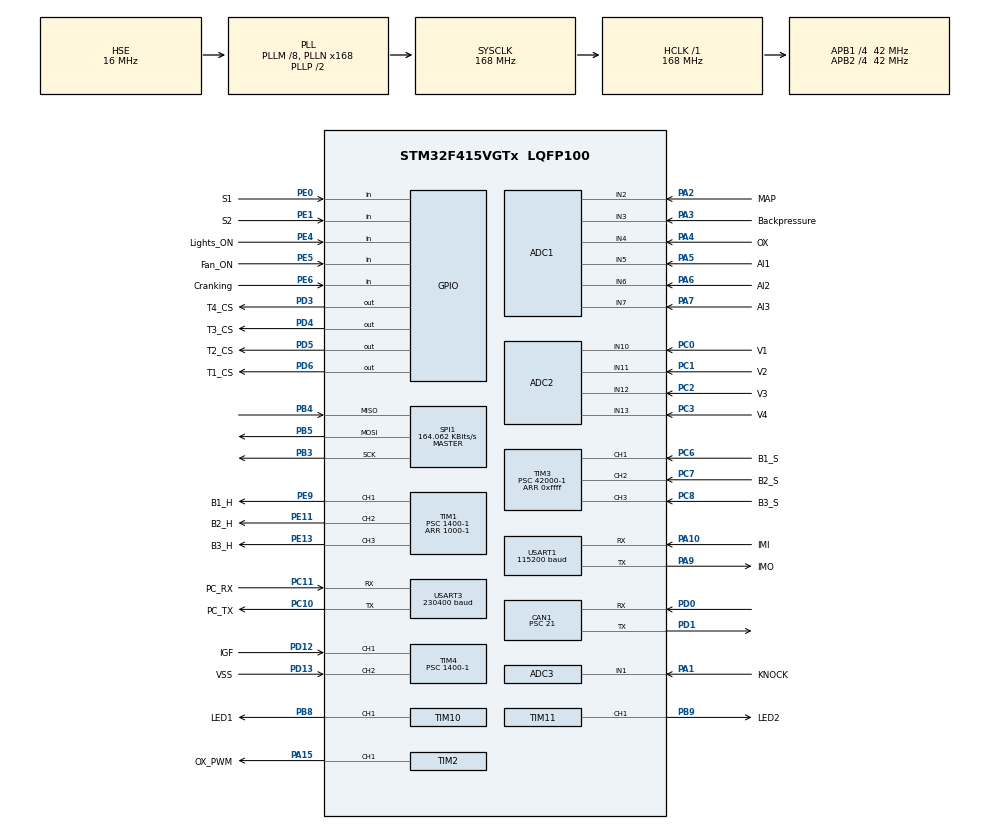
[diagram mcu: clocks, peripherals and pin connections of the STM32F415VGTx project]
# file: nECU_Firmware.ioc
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ADC1.Channel-18\#ChannelRegularConversion=ADC_CHANNEL_3
ADC1.Channel-19\#ChannelRegularConversion=ADC_CHANNEL_4
ADC1.Channel-20\#ChannelRegularConversion=ADC_CHANNEL_5
ADC1.Channel-21\#ChannelRegularConversion=ADC_CHANNEL_6
ADC1.Channel-22\#ChannelRegularConversion=ADC_CHANNEL_7
ADC1.Channel-23\#ChannelRegularConversion=ADC_CHANNEL_TEMPSENSOR
ADC1.Channel-24\#ChannelRegularConversion=ADC_CHANNEL_VREFINT
ADC1.Channel-3\#ChannelRegularConversion=ADC_CHANNEL_2
ADC1.ClockPrescaler=ADC_CLOCK_SYNC_PCLK_DIV8
ADC1.ContinuousConvMode=ENABLE
ADC1.DMAContinuousRequests=ENABLE
ADC1.DiscontinuousConvMode=DISABLE
ADC1.EOCSelection=ADC_EOC_SEQ_CONV
ADC1.ExternalTrigConv=ADC_SOFTWARE_START
ADC1.InjNumberOfConversion=0
ADC1.NbrOfConversion=8
ADC1.NbrOfConversionFlag=1
ADC1.Rank-18\#ChannelRegularConversion=2
ADC1.Rank-19\#ChannelRegularConversion=3
ADC1.Rank-20\#ChannelRegularConversion=4
ADC1.Rank-21\#ChannelRegularConversion=5
ADC1.Rank-22\#ChannelRegularConversion=6
ADC1.Rank-23\#ChannelRegularConversion=7
ADC1.Rank-24\#ChannelRegularConversion=8
ADC1.SamplingTime-18\#ChannelRegularConversion=ADC_SAMPLETIME_480CYCLES
ADC1.SamplingTime-19\#ChannelRegularConversion=ADC_SAMPLETIME_480CYCLES
ADC1.SamplingTime-20\#ChannelRegularConversion=ADC_SAMPLETIME_480CYCLES
ADC1.SamplingTime-21\#ChannelRegularConversion=ADC_SAMPLETIME_480CYCLES
ADC1.SamplingTime-22\#ChannelRegularConversion=ADC_SAMPLETIME_480CYCLES
ADC1.SamplingTime-23\#ChannelRegularConversion=ADC_SAMPLETIME_480CYCLES
ADC1.SamplingTime-24\#ChannelRegularConversion=ADC_SAMPLETIME_480CYCLES
ADC1.SamplingTime-3\#ChannelRegularConversion=ADC_SAMPLETIME_480CYCLES
ADC1.ScanConvMode=ENABLE
ADC1.master=1
ADC2.Channel-1\#ChannelRegularConversion=ADC_CHANNEL_10
ADC2.Channel-2\#ChannelRegularConversion=ADC_CHANNEL_11
ADC2.Channel-3\#ChannelRegularConversion=ADC_CHANNEL_12
ADC2.Channel-4\#ChannelRegularConversion=ADC_CHANNEL_13
ADC2.ClockPrescaler=ADC_CLOCK_SYNC_PCLK_DIV8
ADC2.ContinuousConvMode=ENABLE
ADC2.DMAContinuousRequests=ENABLE
ADC2.EOCSelection=ADC_EOC_SEQ_CONV
ADC2.ExternalTrigConv=ADC_SOFTWARE_START
ADC2.NbrOfConversion=4
ADC2.NbrOfConversionFlag=1
ADC2.Rank-1\#ChannelRegularConversion=1
ADC2.Rank-2\#ChannelRegularConversion=2
ADC2.Rank-3\#ChannelRegularConversion=3
ADC2.Rank-4\#ChannelRegularConversion=4
ADC2.SamplingTime-1\#ChannelRegularConversion=ADC_SAMPLETIME_480CYCLES
ADC2.SamplingTime-2\#ChannelRegularConversion=ADC_SAMPLETIME_480CYCLES
ADC2.SamplingTime-3\#ChannelRegularConversion=ADC_SAMPLETIME_480CYCLES
ADC2.SamplingTime-4\#ChannelRegularConversion=ADC_SAMPLETIME_480CYCLES
ADC2.ScanConvMode=ENABLE
ADC3.Channel-1\#ChannelRegularConversion=ADC_CHANNEL_1
ADC3.ClockPrescaler=ADC_CLOCK_SYNC_PCLK_DIV8
ADC3.ContinuousConvMode=DISABLE
ADC3.DMAContinuousRequests=ENABLE
ADC3.EOCSelection=ADC_EOC_SEQ_CONV
ADC3.ExternalTrigConv=ADC_EXTERNALTRIGCONV_T8_TRGO
ADC3.NbrOfConversion=1
ADC3.NbrOfConversionFlag=1
ADC3.Rank-1\#ChannelRegularConversion=1
ADC3.SamplingTime-1\#ChannelRegularConversion=ADC_SAMPLETIME_84CYCLES
ADC3.ScanConvMode=ENABLE
CAN1.ABOM=ENABLE
CAN1.AWUM=ENABLE
CAN1.BS1=CAN_BS1_2TQ
CAN1.BS2=CAN_BS2_1TQ
CAN1.CalculateBaudRate=500000
CAN1.CalculateTimeBit=2000
CAN1.CalculateTimeQuantum=500.0
CAN1.Prescaler=21
CAN1.SJW=CAN_SJW_2TQ
CAN1.TTCM=DISABLE
Dma.ADC1.3.Direction=DMA_PERIPH_TO_MEMORY
Dma.ADC1.3.FIFOMode=DMA_FIFOMODE_DISABLE
Dma.ADC1.3.Instance=DMA2_Stream0
Dma.ADC1.3.MemDataAlignment=DMA_MDATAALIGN_HALFWORD
Dma.ADC1.3.MemInc=DMA_MINC_ENABLE
Dma.ADC1.3.Mode=DMA_CIRCULAR
Dma.ADC1.3.PeriphDataAlignment=DMA_PDATAALIGN_HALFWORD
Dma.ADC1.3.PeriphInc=DMA_PINC_DISABLE
Dma.ADC1.3.Priority=DMA_PRIORITY_LOW
Dma.ADC2.0.Direction=DMA_PERIPH_TO_MEMORY
Dma.ADC2.0.FIFOMode=DMA_FIFOMODE_DISABLE
Dma.ADC2.0.Instance=DMA2_Stream3
Dma.ADC2.0.MemDataAlignment=DMA_MDATAALIGN_HALFWORD
Dma.ADC2.0.MemInc=DMA_MINC_ENABLE
Dma.ADC2.0.Mode=DMA_CIRCULAR
Dma.ADC2.0.PeriphDataAlignment=DMA_PDATAALIGN_HALFWORD
Dma.ADC2.0.PeriphInc=DMA_PINC_DISABLE
Dma.ADC2.0.Priority=DMA_PRIORITY_LOW
Dma.ADC3.1.Direction=DMA_PERIPH_TO_MEMORY
Dma.ADC3.1.FIFOMode=DMA_FIFOMODE_DISABLE
Dma.ADC3.1.Instance=DMA2_Stream1
Dma.ADC3.1.MemDataAlignment=DMA_MDATAALIGN_HALFWORD
Dma.ADC3.1.MemInc=DMA_MINC_ENABLE
Dma.ADC3.1.Mode=DMA_CIRCULAR
Dma.ADC3.1.PeriphDataAlignment=DMA_PDATAALIGN_HALFWORD
Dma.ADC3.1.PeriphInc=DMA_PINC_DISABLE
Dma.ADC3.1.Priority=DMA_PRIORITY_HIGH
Dma.Request0=ADC2
Dma.Request1=ADC3
Dma.Request2=USART1_TX
Dma.Request3=ADC1
Dma.USART1_TX.2.Direction=DMA_MEMORY_TO_PERIPH
Dma.USART1_TX.2.FIFOMode=DMA_FIFOMODE_DISABLE
Dma.USART1_TX.2.Instance=DMA2_Stream7
Dma.USART1_TX.2.MemDataAlignment=DMA_MDATAALIGN_BYTE
Dma.USART1_TX.2.MemInc=DMA_MINC_ENABLE
Dma.USART1_TX.2.Mode=DMA_NORMAL
Dma.USART1_TX.2.PeriphDataAlignment=DMA_PDATAALIGN_BYTE
Dma.USART1_TX.2.PeriphInc=DMA_PINC_DISABLE
Dma.USART1_TX.2.Priority=DMA_PRIORITY_HIGH
Mcu.Family=STM32F4
Mcu.Name=STM32F415VGTx
Mcu.Package=LQFP100
NVIC.CAN1_RX0_IRQn=true\:0\:3\:false\:false\:true\:true\:true\:true
NVIC.DMA2_Stream0_IRQn=true\:0\:0\:false\:false\:true\:true\:true\:true
NVIC.DMA2_Stream1_IRQn=true\:0\:2\:true\:false\:true\:false\:true\:true
NVIC.DMA2_Stream3_IRQn=true\:0\:3\:true\:false\:true\:false\:true\:true
NVIC.PriorityGroup=NVIC_PRIORITYGROUP_2
NVIC.SPI1_IRQn=true\:0\:2\:true\:false\:true\:true\:true\:true
NVIC.TIM3_IRQn=true\:1\:2\:true\:false\:true\:true\:true\:true
NVIC.TIM4_IRQn=true\:1\:3\:true\:false\:true\:true\:true\:true
NVIC.USART3_IRQn=true\:1\:1\:true\:false\:true\:true\:true\:true
PA1.GPIO_Label=KNOCK
PA1.Signal=ADCx_IN1
PA10.GPIO_Label=IMI
PA10.Mode=Asynchronous
PA10.Signal=USART1_RX
PA13.Mode=Serial_Wire
PA13.Signal=SYS_JTMS-SWDIO
PA14.Mode=Serial_Wire
PA14.Signal=SYS_JTCK-SWCLK
PA15.GPIO_Label=OX_PWM
PA15.Signal=S_TIM2_CH1_ETR
PA2.GPIO_Label=MAP
PA2.Signal=ADCx_IN2
PA3.GPIO_Label=Backpressure
PA3.Signal=ADCx_IN3
PA4.GPIO_Label=OX
PA4.Signal=ADCx_IN4
PA5.GPIO_Label=AI1
PA5.Signal=ADCx_IN5
PA6.GPIO_Label=AI2
PA6.Signal=ADCx_IN6
PA7.GPIO_Label=AI3
PA7.Signal=ADCx_IN7
PA9.GPIO_Label=IMO
PA9.Mode=Asynchronous
PA9.Signal=USART1_TX
PB3.Mode=Full_Duplex_Master
PB3.Signal=SPI1_SCK
PB4.Mode=Full_Duplex_Master
PB4.Signal=SPI1_MISO
PB5.Mode=Full_Duplex_Master
PB5.Signal=SPI1_MOSI
PB8.GPIO_Label=LED1
PB8.Signal=S_TIM10_CH1
PB9.GPIO_Label=LED2
PB9.Signal=S_TIM11_CH1
PC0.GPIO_Label=V1
PC0.Signal=ADCx_IN10
PC1.GPIO_Label=V2
PC1.Signal=ADCx_IN11
PC10.GPIO_Label=PC_TX
PC10.Mode=Asynchronous
PC10.Signal=USART3_TX
PC11.GPIO_Label=PC_RX
PC11.Mode=Asynchronous
PC11.Signal=USART3_RX
PC14-OSC32_IN.Mode=LSE-External-Oscillator
PC14-OSC32_IN.Signal=RCC_OSC32_IN
PC15-OSC32_OUT.Mode=LSE-External-Oscillator
PC15-OSC32_OUT.Signal=RCC_OSC32_OUT
PC2.GPIO_Label=V3
PC2.Signal=ADCx_IN12
PC3.GPIO_Label=V4
PC3.Signal=ADCx_IN13
PC6.GPIO_Label=B1_S
PC6.GPIO_PuPd=GPIO_PULLDOWN
PC6.Signal=S_TIM3_CH1
PC7.GPIO_Label=B2_S
PC7.GPIO_PuPd=GPIO_PULLDOWN
PC7.Signal=S_TIM3_CH2
PC8.GPIO_Label=B3_S
PC8.GPIO_PuPd=GPIO_PULLDOWN
PC8.Signal=S_TIM3_CH3
PD0.Mode=CAN_Activate
PD0.Signal=CAN1_RX
PD1.Mode=CAN_Activate
PD1.Signal=CAN1_TX
PD12.GPIO_Label=IGF
PD12.GPIO_PuPd=GPIO_PULLDOWN
PD12.Signal=S_TIM4_CH1
PD13.GPIO_Label=VSS
PD13.GPIO_PuPd=GPIO_PULLDOWN
PD13.Signal=S_TIM4_CH2
PD3.GPIO_Label=T4_CS
PD3.PinState=GPIO_PIN_SET
PD3.Signal=GPIO_Output
PD4.GPIO_Label=T3_CS
PD4.PinState=GPIO_PIN_SET
PD4.Signal=GPIO_Output
PD5.GPIO_Label=T2_CS
PD5.PinState=GPIO_PIN_SET
PD5.Signal=GPIO_Output
PD6.GPIO_Label=T1_CS
PD6.PinState=GPIO_PIN_SET
PD6.Signal=GPIO_Output
PE0.GPIO_Label=S1
PE0.Signal=GPIO_Input
PE1.GPIO_Label=S2
PE1.Signal=GPIO_Input
PE11.GPIO_Label=B2_H
PE11.Signal=S_TIM1_CH2
PE13.GPIO_Label=B3_H
PE13.Signal=S_TIM1_CH3
PE4.GPIO_Label=Lights_ON
PE4.Signal=GPIO_Input
PE5.GPIO_Label=Fan_ON
PE5.Signal=GPIO_Input
PE6.GPIO_Label=Cranking
PE6.GPIO_PuPd=GPIO_NOPULL
PE6.Signal=GPIO_Input
PE9.GPIO_Label=B1_H
PE9.Signal=S_TIM1_CH1
PH0-OSC_IN.Mode=HSE-External-Oscillator
PH0-OSC_IN.Signal=RCC_OSC_IN
PH1-OSC_OUT.Mode=HSE-External-Oscillator
PH1-OSC_OUT.Signal=RCC_OSC_OUT
ProjectManager.HeapSize=0x800
ProjectManager.StackSize=0x1000
ProjectManager.TargetToolchain=STM32CubeIDE
RCC.48MHZClocksFreq_Value=84000000
RCC.AHBFreq_Value=168000000
RCC.APB1CLKDivider=RCC_HCLK_DIV4
RCC.APB1Freq_Value=42000000
RCC.APB1TimFreq_Value=84000000
RCC.APB2CLKDivider=RCC_HCLK_DIV4
RCC.APB2Freq_Value=42000000
RCC.APB2TimFreq_Value=84000000
RCC.CortexFreq_Value=168000000
RCC.HCLKFreq_Value=168000000
RCC.HSE_VALUE=16000000
RCC.HSI_VALUE=16000000
RCC.PLLM=8
RCC.PLLN=168
RCC.PLLSourceVirtual=RCC_PLLSOURCE_HSE
RCC.SYSCLKFreq_VALUE=168000000
RCC.SYSCLKSource=RCC_SYSCLKSOURCE_PLLCLK
RCC.VCOOutputFreq_Value=336000000
SH.ADCx_IN1.0=ADC3_IN1,IN1
SH.ADCx_IN10.0=ADC2_IN10,IN10
SH.ADCx_IN11.0=ADC2_IN11,IN11
SH.ADCx_IN12.0=ADC2_IN12,IN12
SH.ADCx_IN13.0=ADC2_IN13,IN13
SH.ADCx_IN2.0=ADC1_IN2,IN2
SH.ADCx_IN3.0=ADC1_IN3,IN3
SH.ADCx_IN4.0=ADC1_IN4,IN4
SH.ADCx_IN5.0=ADC1_IN5,IN5
SH.ADCx_IN6.0=ADC1_IN6,IN6
SH.ADCx_IN7.0=ADC1_IN7,IN7
SH.S_TIM10_CH1.0=TIM10_CH1,PWM Generation1 CH1
SH.S_TIM11_CH1.0=TIM11_CH1,PWM Generation1 CH1
SH.S_TIM1_CH1.0=TIM1_CH1,PWM Generation1 CH1
SH.S_TIM1_CH2.0=TIM1_CH2,PWM Generation2 CH2
SH.S_TIM1_CH3.0=TIM1_CH3,PWM Generation3 CH3
SH.S_TIM2_CH1_ETR.0=TIM2_CH1,PWM Generation1 CH1
SH.S_TIM3_CH1.0=TIM3_CH1,Input_Capture1_from_TI1
SH.S_TIM3_CH2.0=TIM3_CH2,Input_Capture2_from_TI2
SH.S_TIM3_CH3.0=TIM3_CH3,Input_Capture3_from_TI3
SH.S_TIM4_CH1.0=TIM4_CH1,Input_Capture1_from_TI1
SH.S_TIM4_CH2.0=TIM4_CH2,Input_Capture2_from_TI2
SPI1.BaudRatePrescaler=SPI_BAUDRATEPRESCALER_256
SPI1.CalculateBaudRate=164.062 KBits/s
SPI1.Direction=SPI_DIRECTION_2LINES
SPI1.Mode=SPI_MODE_MASTER
SPI1.VirtualType=VM_MASTER
TIM1.AutoReloadPreload=TIM_AUTORELOAD_PRELOAD_ENABLE
TIM1.Channel-PWM\ Generation1\ CH1=TIM_CHANNEL_1
TIM1.Channel-PWM\ Generation2\ CH2=TIM_CHANNEL_2
TIM1.Channel-PWM\ Generation3\ CH3=TIM_CHANNEL_3
TIM1.ClockDivision=TIM_CLOCKDIVISION_DIV1
TIM1.Period=1000-1
TIM1.Prescaler=1400-1
TIM1.TIM_MasterOutputTrigger=TIM_TRGO_UPDATE
TIM1.TIM_MasterSlaveMode=TIM_MASTERSLAVEMODE_DISABLE
TIM10.AutoReloadPreload=TIM_AUTORELOAD_PRELOAD_ENABLE
TIM10.Channel=TIM_CHANNEL_1
TIM10.Period=1000-1
TIM10.Prescaler=1400-1
TIM10.Pulse=500
TIM11.AutoReloadPreload=TIM_AUTORELOAD_PRELOAD_ENABLE
TIM11.Channel=TIM_CHANNEL_1
TIM11.OCPolarity_1=TIM_OCPOLARITY_HIGH
TIM11.Period=1000-1
TIM11.Prescaler=1400-1
TIM11.Pulse=500
TIM2.AutoReloadPreload=TIM_AUTORELOAD_PRELOAD_ENABLE
TIM2.Channel-PWM\ Generation1\ CH1=TIM_CHANNEL_1
TIM2.OCPolarity_1=TIM_OCPOLARITY_HIGH
TIM2.Period=100-1
TIM2.Prescaler=16400-1
TIM3.AutoReloadPreload=TIM_AUTORELOAD_PRELOAD_ENABLE
TIM3.Channel-Input_Capture1_from_TI1=TIM_CHANNEL_1
TIM3.Channel-Input_Capture2_from_TI2=TIM_CHANNEL_2
TIM3.Channel-Input_Capture3_from_TI3=TIM_CHANNEL_3
TIM3.ICFilter_CH1=15
TIM3.ICFilter_CH2=15
TIM3.ICFilter_CH3=15
TIM3.ICPolarity_CH1=TIM_INPUTCHANNELPOLARITY_BOTHEDGE
TIM3.ICPolarity_CH2=TIM_INPUTCHANNELPOLARITY_BOTHEDGE
TIM3.ICPolarity_CH3=TIM_INPUTCHANNELPOLARITY_BOTHEDGE
TIM3.Period=0xffff
TIM3.Prescaler=42000-1
TIM4.Channel-Input_Capture1_from_TI1=TIM_CHANNEL_1
TIM4.Channel-Input_Capture2_from_TI2=TIM_CHANNEL_2
TIM4.ClockDivision=TIM_CLOCKDIVISION_DIV1
TIM4.ICFilter_CH1=16-1
TIM4.ICFilter_CH2=16-1
TIM4.ICPolarity_CH1=TIM_INPUTCHANNELPOLARITY_BOTHEDGE
TIM4.ICPolarity_CH2=TIM_INPUTCHANNELPOLARITY_BOTHEDGE
TIM4.ICPrescaler-Input_Capture1_from_TI1=TIM_ICPSC_DIV1
TIM4.Prescaler=1400-1
TIM6.AutoReloadPreload=TIM_AUTORELOAD_PRELOAD_ENABLE
TIM6.Period=255
TIM6.Prescaler=8400-1
TIM8.AutoReloadPreload=TIM_AUTORELOAD_PRELOAD_DISABLE
TIM8.Period=20-1
TIM8.Prescaler=84-1
TIM8.TIM_MasterOutputTrigger=TIM_TRGO_UPDATE
USART1.BaudRate=115200
USART1.Mode=MODE_TX_RX
USART1.Parity=PARITY_EVEN
USART1.VirtualMode=VM_ASYNC
USART1.WordLength=WORDLENGTH_9B
USART3.BaudRate=230400
USART3.VirtualMode=VM_ASYNC
VP_ADC1_TempSens_Input.Mode=IN-TempSens
VP_ADC1_Vref_Input.Mode=IN-Vrefint
VP_CRC_VS_CRC.Mode=CRC_Activate
VP_TIM10_VS_ClockSourceINT.Mode=Enable_Timer
VP_TIM11_VS_ClockSourceINT.Mode=Enable_Timer
VP_TIM1_VS_ClockSourceINT.Mode=Internal
VP_TIM2_VS_ClockSourceINT.Mode=Internal
VP_TIM3_VS_ClockSourceINT.Mode=Internal
VP_TIM4_VS_ClockSourceINT.Mode=Internal
VP_TIM6_VS_ClockSourceINT.Mode=Enable_Timer
VP_TIM8_VS_ClockSourceINT.Mode=Internal
board=custom

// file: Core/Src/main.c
/* USER CODE BEGIN Header */
/**
 ******************************************************************************
 * @file           : main.c
 * @brief          : Main program body
 ******************************************************************************
 * @attention
 *
 * Copyright (c) 2024 STMicroelectronics.
 * All rights reserved.
 *
 * This software is licensed under terms that can be found in the LICENSE file
 * in the root directory of this software component.
 * If no LICENSE file comes with this software, it is provided AS-IS.
 *
 ******************************************************************************
 */
/* USER CODE END Header */
#include "main.h"
#include "adc.h"
#include "can.h"
#include "crc.h"
#include "dma.h"
#include "spi.h"
#include "tim.h"
#include "usart.h"
#include "gpio.h"

/* USER CODE BEGIN Includes */
#include "nECU.h"
/* USER CODE END Includes */

void SystemClock_Config(void);

int main(void)
{

  /* MCU Configuration--------------------------------------------------------*/

  /* Reset of all peripherals, Initializes the Flash interface and the Systick. */
  HAL_Init();

  /* Configure the system clock */
  SystemClock_Config();

  /* Initialize all configured peripherals */
  MX_DMA_Init();
  MX_GPIO_Init();
  MX_ADC1_Init();
  MX_ADC2_Init();
  MX_ADC3_Init();
  MX_TIM1_Init();
  MX_TIM2_Init();
  MX_TIM3_Init();
  MX_TIM4_Init();
  MX_TIM8_Init();
  MX_CAN1_Init();
  MX_USART1_UART_Init();
  MX_SPI1_Init();
  MX_CRC_Init();
  MX_USART3_UART_Init();
  MX_TIM6_Init();
  MX_TIM10_Init();
  MX_TIM11_Init();
  /* USER CODE BEGIN 2 */
  nECU_Start();
  /* USER CODE END 2 */

  /* Infinite loop */
  while (1)
  {

    /* USER CODE BEGIN 3 */
    nECU_main();
  }
  /* USER CODE END 3 */
}

void SystemClock_Config(void)
{
  RCC_OscInitTypeDef RCC_OscInitStruct = {0};
  RCC_ClkInitTypeDef RCC_ClkInitStruct = {0};

  /** Configure the main internal regulator output voltage
  */
  __HAL_RCC_PWR_CLK_ENABLE();
  __HAL_PWR_VOLTAGESCALING_CONFIG(PWR_REGULATOR_VOLTAGE_SCALE1);

  /** Initializes the RCC Oscillators according to the specified parameters
  * in the RCC_OscInitTypeDef structure.
  */
  RCC_OscInitStruct.OscillatorType = RCC_OSCILLATORTYPE_HSE;
  RCC_OscInitStruct.HSEState = RCC_HSE_ON;
  RCC_OscInitStruct.PLL.PLLState = RCC_PLL_ON;
  RCC_OscInitStruct.PLL.PLLSource = RCC_PLLSOURCE_HSE;
  RCC_OscInitStruct.PLL.PLLM = 8;
  RCC_OscInitStruct.PLL.PLLN = 168;
  RCC_OscInitStruct.PLL.PLLP = RCC_PLLP_DIV2;
  RCC_OscInitStruct.PLL.PLLQ = 4;
  if (HAL_RCC_OscConfig(&RCC_OscInitStruct) != HAL_OK)
  {
    Error_Handler();
  }

  /** Initializes the CPU, AHB and APB buses clocks
  */
  RCC_ClkInitStruct.ClockType = RCC_CLOCKTYPE_HCLK|RCC_CLOCKTYPE_SYSCLK
                              |RCC_CLOCKTYPE_PCLK1|RCC_CLOCKTYPE_PCLK2;
  RCC_ClkInitStruct.SYSCLKSource = RCC_SYSCLKSOURCE_PLLCLK;
  RCC_ClkInitStruct.AHBCLKDivider = RCC_SYSCLK_DIV1;
  RCC_ClkInitStruct.APB1CLKDivider = RCC_HCLK_DIV4;
  RCC_ClkInitStruct.APB2CLKDivider = RCC_HCLK_DIV4;

  if (HAL_RCC_ClockConfig(&RCC_ClkInitStruct, FLASH_LATENCY_5) != HAL_OK)
  {
    Error_Handler();
  }
}

void Error_Handler(void)
{
  __disable_irq();
  while (1)
  {
  }
}
